# DMM register map
Vendor: Texas Instruments
Peripheral module from a debugger description file (folder omap4430).
Registers are 32-bit, access not given, reset values left out (the file's numbers can be read two ways) unless marked. A register's access mark holds for its fields unless they carry their own. Offsets are as the file gives them; lines under a group give offsets from that group; [hi:lo] are bit positions; {n}, {i} and the like mark numbered series; 'fields as' and 'values as' point back to an identical list; <NAME> marks a mode.

## DMM
0x00 DMM_REVISION ro — DMM Revision Number
  [31:0] REVISION — Revision Number
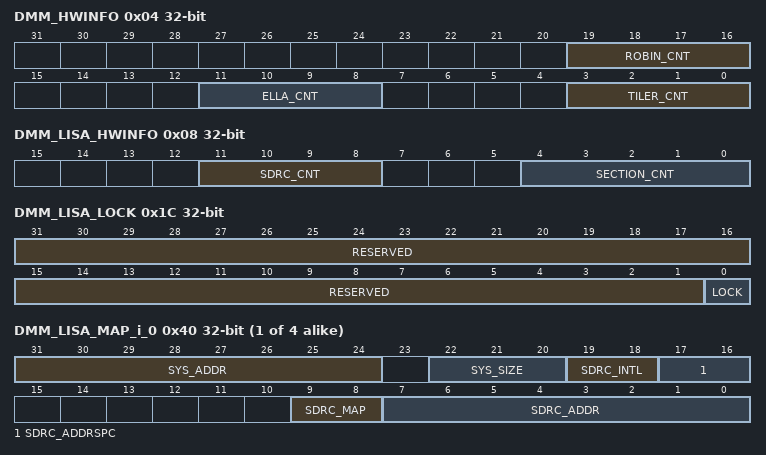
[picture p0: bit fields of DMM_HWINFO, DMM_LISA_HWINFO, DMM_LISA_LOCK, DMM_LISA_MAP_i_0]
0x04 DMM_HWINFO ro — DMM hardware configuration
  [19:16] ROBIN_CNT — Number of ROBIN in the DMM
  [11:8] ELLA_CNT — Number of ELLA in the DMM
  [3:0] TILER_CNT — Number of TILER in the DMM
0x08 DMM_LISA_HWINFO ro — DMM hardware configuration for LISA
  [11:8] SDRC_CNT — Number of attached SDRAM controllers
  [4:0] SECTION_CNT — Number of DMM sections
0x10 DMM_SYSCONFIG — DMM clock management configuration
  [3:2] IDLE_MODE rw — Configuration of the local target state management mode.
    0=Force-idle mode: local target's idle state follows (acknowledges) the system's idle requests unconditionally, that is, regardless of the IP module's internal requirements. Backup mode, for debug only.; 1=No-idle mode: local target never enters idle state. Backup mode, for debug only; 2=Smart-idle mode: local target's idle state eventually follows (acknowledges) the system's idle requests, depending on the IP module's internal requirements. IP module shall not generate (IRQ- or DMA-request-related) wakeup events.
0x1C DMM_LISA_LOCK access per field — DMM memory mapping lock
  [31:1] RESERVED ro — Should be written as 0
  [0] LOCK rw — DMM lock map
    0=LOCK_0_w (No effect (clear on reset only)); 0=LOCK_0_r (un-locked); 1=LOCK_1_r (locked); 1=LOCK_1_w (Locking registers)
{0x40+4i} DMM_LISA_MAP_i_{i} (i=0..3) — DMM memory mapping register
  [31:24] SYS_ADDR rw — DMM system section address MSB for view mapping i
  [22:20] SYS_SIZE rw — DMM system section size for view mapping i
    0=16-MiB section; 1=32-MiB section; 2=64-MiB section; 3=128-MiB section; 4=256-MiB section; 5=512-MiB section; 6=1-GiB section; 7=2-GiB section
  [19:18] SDRC_INTL rw — SDRAM controller interleaving mode 0x0: No interleaving 0x1: 128-byte interleaving 0x2: 256-byte interleaving 0x3: 512-byte interleaving The 128-/256-/512-byte interleaving applies only to nontiled regions. If accesses are made to tiled regions, interleaving is forced to 1kiB. SDRC_INTL is don't care if SDRC_MAP is not 0x3 (no interleaving).
  [17:16] SDRC_ADDRSPC rw — SDRAM controller address space for view mapping i
  [9:8] SDRC_MAP rw — SDRAM controller mapping for view mapping i 0x0: Un-mapped 0x1: Mapped on EMIF1 only (not interleaved) 0x2: Mapped on EMIF2 only (not interleaved) 0x3: Mapped on EMIF1 and EMIF2 (interleaved) To enable interleaving, SDRC_MAP must be 0x3 and SDRC_INTL must be a nonzero value.
  [7:0] SDRC_ADDR rw — SDRAM controller address MSB for view mapping i
0x208 DMM_TILER_HWINFO ro — DMM hardware configuration for TILER
  [4:0] OR_CNT — Number of TILER orientation entries
    1=OR_CNT_1_r (One orientation entry); 2=OR_CNT_2_r (Two orientation entries); 4=OR_CNT_4_r (Four orientation entries); 8=OR_CNT_8_r (Eight orientation entries); 16=OR_CNT_16_r (Sixteen orientation entries)
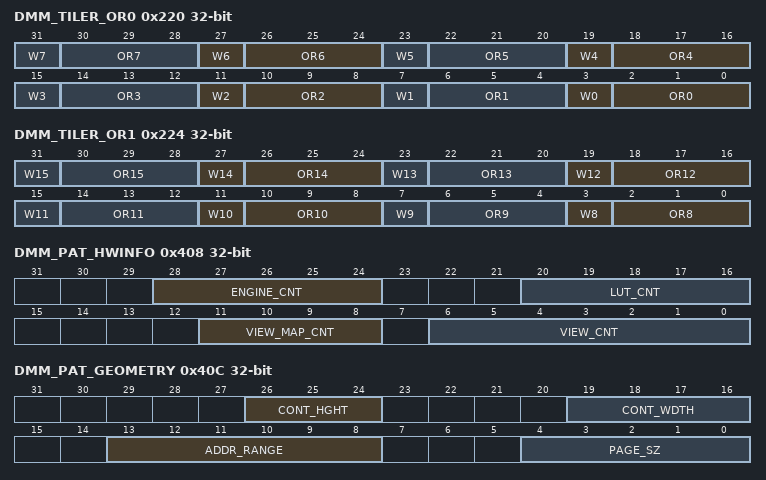
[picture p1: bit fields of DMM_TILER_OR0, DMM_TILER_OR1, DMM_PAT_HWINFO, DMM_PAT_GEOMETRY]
0x220 DMM_TILER_OR0 rw — DMM TILER orientation (initiators 0 to 7)
  [4n+3] W{n} (n=0..7) — Write-enable for OR{n} bit field
    0=W{n}_0_w (OR{n} field is unchanged); 1=W{n}_1_w (OR{n} field is updated)
  [4n+2:4n] OR{n} (n=0..7) — Orientation for initiator {n}
0x224 DMM_TILER_OR1 rw — DMM TILER orientation (initiators 8 to 15)
  [4n-29] W{n} (n=8..15) — Write-enable for OR{n} bit field
    values as DMM_TILER_OR0.W0
  [4n-30:4n-32] OR{n} (n=8..15) — Orientation for initiator {n}
0x408 DMM_PAT_HWINFO ro — DMM hardware configuration for PAT
  [28:24] ENGINE_CNT — Number of PAT refill engines
  [20:16] LUT_CNT — Number of PAT LUT for page-grained physical address translation
  [11:8] VIEW_MAP_CNT — Number of internal PAT view mappings.
    1=VIEW_MAP_CNT_1_r (One view map); 2=VIEW_MAP_CNT_2_r (Two view maps); 4=VIEW_MAP_CNT_4_r (Four view maps); 8=VIEW_MAP_CNT_8_r (Eight view maps)
  [6:0] VIEW_CNT — Number of PAT view entries
    1=VIEW_CNT_1_r (One view entry); 2=VIEW_CNT_2_r (Two view entries); 4=VIEW_CNT_4_r (Four view entries); 8=VIEW_CNT_8_r (Eight view entries); 16=VIEW_CNT_16_r (Sixteen view entries); 32=VIEW_CNT_32_r (Thirty-two view entries); 64=VIEW_CNT_64_r (Sixty-four view entries)
0x40C DMM_PAT_GEOMETRY ro — PAT geometry-related settings
  [26:24] CONT_HGHT — Container height in pages
    1=CONT_HGHT_1_r (Container height of 32 pages); 2=CONT_HGHT_2_r (Container height of 64 pages); 4=CONT_HGHT_4_r (Container height of 128 pages)
  [19:16] CONT_WDTH — Container width in pages
    2=CONT_WDTH_2_r (Container width of 64 pages); 4=CONT_WDTH_4_r (Container width of 128 pages); 8=CONT_WDTH_8_r (Container width of 256 pages)
  [13:8] ADDR_RANGE — PAT output physical address range
    1=ADDR_RANGE_1_r (128-MiB range); 2=ADDR_RANGE_2_r (256-MiB range); 4=ADDR_RANGE_4_r (512-MiB range); 8=ADDR_RANGE_8_r (1-GiB range); 16=ADDR_RANGE_16_r (2-GiB range); 32=ADDR_RANGE_32_r (4-GiB range)
  [4:0] PAGE_SZ — Page size in 4-kiB granularity
    1=PAGE_SZ_1_r (4-kiB page); 4=PAGE_SZ_4_r (16-kiB page); 16=PAGE_SZ_16_r (64-kiB page)
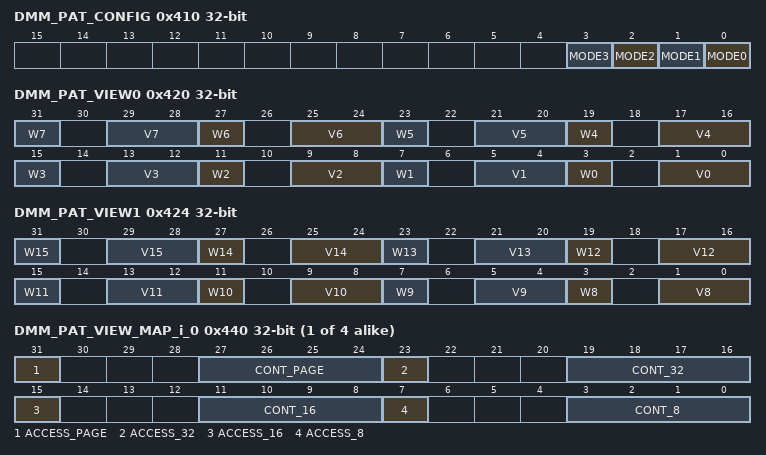
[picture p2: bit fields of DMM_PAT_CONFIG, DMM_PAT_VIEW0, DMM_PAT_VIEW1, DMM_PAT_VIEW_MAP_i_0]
0x410 DMM_PAT_CONFIG access per field — This is the PAT configuration register aimed at defining the major PAT configuration of each refill engine.
  [all] fields
    0=Normal mode; 1=Direct LUT access
  [n] MODE{n} rw (n=0..3) — Mode of refill engine {n}
0x420 DMM_PAT_VIEW0 — DMM PAT View register (initiators 0 to 7)
  [4n+3] W{n} rw (n=0..7) — Write-enable for V{n} bit field
    0=W{n}_0_w (V{n} field is unchanged); 1=W{n}_1_w (V{n} field is updated)
  [4n+1:4n] V{n} rw (n=0..7) — PAT view for initiator {n}
0x424 DMM_PAT_VIEW1 — DMM PAT view register (initiators 8 to 15)
  [4n-29] W{n} rw (n=8..15) — Write-enable for V{n} bit field
    values as DMM_PAT_VIEW0.W0
  [4n-31:4n-32] V{n} rw (n=8..15) — PAT view for initiator {n}
{0x440+4i} DMM_PAT_VIEW_MAP_i_{i} (i=0..3) — PAT view mapping register
  [31] ACCESS_PAGE rw — Kind of access for this page mode container in view mapping i
    0=Direct access, container base address given in CONT_PAGE; 1=Indirect access through the LUT indexed by CONT_PAGE
  [27:24] CONT_PAGE rw — Container for page mode in view mapping i
  [23] ACCESS_32 rw — Kind of access for this 32-bit mode container in view mapping i
    0=Direct access, container base address given in CONT_32; 1=Indirect access through the LUT indexed by CONT_32
  [19:16] CONT_32 rw — Container for 32-bit mode in view mapping i
  [15] ACCESS_16 rw — Kind of access for this 16-bit mode container in view mapping i
    0=Direct access, container base address given in CONT_16; 1=Indirect access through the LUT indexed by CONT_16
  [11:8] CONT_16 rw — Container for 16-bit mode in view mapping i
  [7] ACCESS_8 rw — Kind of access for this 8-bit mode container in view mapping i
    0=Direct access, container base address given in CONT_8; 1=Indirect access through the LUT indexed by CONT_8
  [3:0] CONT_8 rw — Container for 8-bit mode in view mapping i
0x460 DMM_PAT_VIEW_MAP_BASE — Base address of all view mappings
  [31] BASE_ADDR rw — MSB of the PAT view mapping base address
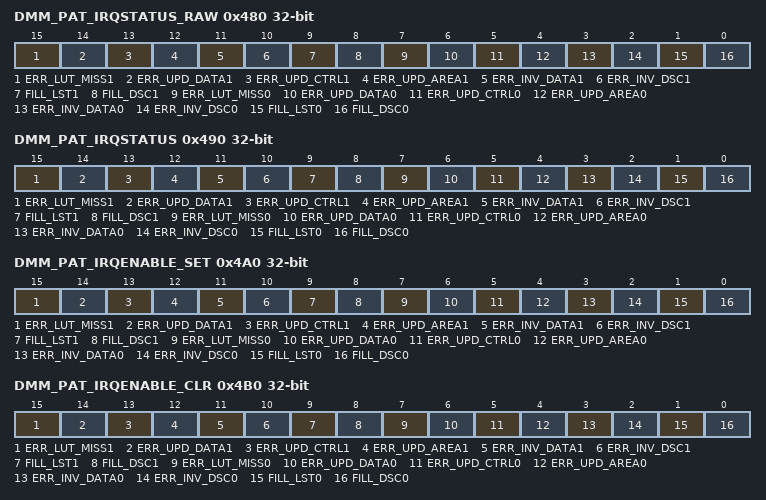
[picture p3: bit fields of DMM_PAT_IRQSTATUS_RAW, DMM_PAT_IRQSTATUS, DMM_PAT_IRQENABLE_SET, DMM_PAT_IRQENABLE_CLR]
0x480 DMM_PAT_IRQSTATUS_RAW — Per-event raw interrupt status vector. Raw status is set even if the related event is not enabled. Write 1 to set the (raw) status, mostly for debug. n = 0 for the first interrupt status raw register, n = 1 for the second interrupt status raw register...
  [15] ERR_LUT_MISS1 — Access to a yet-to-be-refilled area event in area 4.n+1 (access RW W1toSet)
    0=ERR_LUT_MISS1_0_w (Keep current error event); 0=ERR_LUT_MISS1_0_r (No such error event); 1=ERR_LUT_MISS1_1_r (Error event happened); 1=ERR_LUT_MISS1_1_w (Set error event)
  [14] ERR_UPD_DATA1 — Data register update whilst refilling error event in area 4.n+1 (access RW W1toSet)
    0=ERR_UPD_DATA1_0_w (Keep current error event); 0=ERR_UPD_DATA1_0_r (No such error event); 1=ERR_UPD_DATA1_1_r (Error event happened); 1=ERR_UPD_DATA1_1_w (Set error event)
  [13] ERR_UPD_CTRL1 — Control register update whilst refilling error event in area 4.n+1 (access RW W1toSet)
    0=ERR_UPD_CTRL1_0_w (Keep current error event); 0=ERR_UPD_CTRL1_0_r (No such error event); 1=ERR_UPD_CTRL1_1_r (Error event happened); 1=ERR_UPD_CTRL1_1_w (Set error event)
  [12] ERR_UPD_AREA1 — Area register update whilst refilling error event in area 4.n+1 (access RW W1toSet)
    0=ERR_UPD_AREA1_0_w (Keep current error event); 0=ERR_UPD_AREA1_0_r (No such error event); 1=ERR_UPD_AREA1_1_r (Error event happened); 1=ERR_UPD_AREA1_1_w (Set error event)
  [11] ERR_INV_DATA1 — Invalid entry-table pointer error event in area 4.n+1 (access RW W1toSet)
    0=ERR_INV_DATA1_0_w (Keep current error event); 0=ERR_INV_DATA1_0_r (No such error event); 1=ERR_INV_DATA1_1_r (Error event happened); 1=ERR_INV_DATA1_1_w (Set error event)
  [10] ERR_INV_DSC1 — Invalid descriptor pointer error event in area 4.n+1 (access RW W1toSet)
    0=ERR_INV_DSC1_0_w (Keep current error event); 0=ERR_INV_DSC1_0_r (No such error event); 1=ERR_INV_DSC1_1_r (Error event happened); 1=ERR_INV_DSC1_1_w (Set error event)
  [9] FILL_LST1 — End of refill event for the last descriptor in area 4.n+1 (access RW W1toSet)
    0=FILL_LST1_0_w (Keep area 1 refill done event); 0=FILL_LST1_0_r (Area 1 is yet-to-be refilled); 1=FILL_LST1_1_r (Area 1 is refilled); 1=FILL_LST1_1_w (Set area 1 refill done event)
  [8] FILL_DSC1 — End of refill event for any descriptor in area 4.n+1 (access RW W1toSet)
    0=FILL_DSC1_0_w (Keep area 1 refill done event); 0=FILL_DSC1_0_r (Area 1 is yet-to-be refilled); 1=FILL_DSC1_1_r (Area 1 is refilled); 1=FILL_DSC1_1_w (Set area 1 refill done event)
  [7] ERR_LUT_MISS0 — Access to a yet-to-be-refilled area event in area 4.n (access RW W1toSet)
    0=ERR_LUT_MISS0_0_w (Keep current error event); 0=ERR_LUT_MISS0_0_r (No such error event); 1=ERR_LUT_MISS0_1_r (Error event happened); 1=ERR_LUT_MISS0_1_w (Set error event)
  [6] ERR_UPD_DATA0 — Data register update whilst refilling error event in area 4.n (access RW W1toSet)
    0=ERR_UPD_DATA0_0_w (Keep current error event); 0=ERR_UPD_DATA0_0_r (No such error event); 1=ERR_UPD_DATA0_1_r (Error event happened); 1=ERR_UPD_DATA0_1_w (Set error event)
  [5] ERR_UPD_CTRL0 — Control register update whilst refilling error event in area 4.n (access RW W1toSet)
    0=ERR_UPD_CTRL0_0_w (Keep current error event); 0=ERR_UPD_CTRL0_0_r (No such error event); 1=ERR_UPD_CTRL0_1_r (Error event happened); 1=ERR_UPD_CTRL0_1_w (Set error event)
  [4] ERR_UPD_AREA0 — Area register update whilst refilling error event in area 4.n (access RW W1toSet)
    0=ERR_UPD_AREA0_0_w (Keep current error event); 0=ERR_UPD_AREA0_0_r (No such error event); 1=ERR_UPD_AREA0_1_r (Error event happened); 1=ERR_UPD_AREA0_1_w (Set error event)
  [3] ERR_INV_DATA0 — Invalid entry-table pointer error event in area 4.n (access RW W1toSet)
    0=ERR_INV_DATA0_0_w (Keep current error event); 0=ERR_INV_DATA0_0_r (No such error event); 1=ERR_INV_DATA0_1_r (Error event happened); 1=ERR_INV_DATA0_1_w (Set error event)
  [2] ERR_INV_DSC0 — Invalid descriptor pointer error event in area 4.n (access RW W1toSet)
    0=ERR_INV_DSC0_0_w (Keep current error event); 0=ERR_INV_DSC0_0_r (No such error event); 1=ERR_INV_DSC0_1_r (Error event happened); 1=ERR_INV_DSC0_1_w (Set error event)
  [1] FILL_LST0 — End of refill event for the last descriptor in area 4.n (access RW W1toSet)
    0=FILL_LST0_0_w (Keep area 0 refill done event); 0=FILL_LST0_0_r (Area 0 is yet-to-be refilled); 1=FILL_LST0_1_r (Area 0 is refilled); 1=FILL_LST0_1_w (Set area 0 refill done event)
  [0] FILL_DSC0 — End of refill event for any descriptor in area 4.n (access RW W1toSet)
    0=FILL_DSC0_0_w (Keep area 0 refill done event); 0=FILL_DSC0_0_r (Area 0 is yet-to-be refilled); 1=FILL_DSC0_1_r (Area 0 is refilled); 1=FILL_DSC0_1_w (Set area 0 refill done event)
0x490 DMM_PAT_IRQSTATUS — Per-event 'enabled' interrupt status vector. Enabled status is not set unless the event is enabled. Write 1 to clear the status after interrupt has been serviced (raw status gets cleared, that is, even if not enabled). n = 0 for the first interrupt status register, n = 1 for the second interrupt status register...
  [15] ERR_LUT_MISS1 — Access to a yet-to-be-refilled area event in area 4.n+1 (access RW W1toClr)
    0=ERR_LUT_MISS1_0_w (Keep current maskable error event); 0=ERR_LUT_MISS1_0_r (No such error event or this event is masked); 1=ERR_LUT_MISS1_1_r (Error event happened); 1=ERR_LUT_MISS1_1_w (Clear this maskable error event)
  [14] ERR_UPD_DATA1 — Data register update whilst refilling error event in area 4.n+1 (access RW W1toClr)
    0=ERR_UPD_DATA1_0_w (Keep current maskable error event); 0=ERR_UPD_DATA1_0_r (No such error event or this event is masked); 1=ERR_UPD_DATA1_1_r (Error event happened); 1=ERR_UPD_DATA1_1_w (Clear this maskable error event)
  [13] ERR_UPD_CTRL1 — Control register update whilst refilling error event in area 4.n+1 (access RW W1toClr)
    0=ERR_UPD_CTRL1_0_w (Keep current maskable error event); 0=ERR_UPD_CTRL1_0_r (No such error event or this event is masked); 1=ERR_UPD_CTRL1_1_r (Error event happened); 1=ERR_UPD_CTRL1_1_w (Clear this maskable error event)
  [12] ERR_UPD_AREA1 — Area register update whilst refilling error event in area 4.n+1 (access RW W1toClr)
    0=ERR_UPD_AREA1_0_w (Keep current maskable error event); 0=ERR_UPD_AREA1_0_r (No such error event or this event is masked); 1=ERR_UPD_AREA1_1_r (Error event happened); 1=ERR_UPD_AREA1_1_w (Clear this maskable error event)
  [11] ERR_INV_DATA1 — Invalid entry-table pointer error event in area 4.n+1 (access RW W1toClr)
    0=ERR_INV_DATA1_0_w (Keep current maskable error event); 0=ERR_INV_DATA1_0_r (No such error event or this event is masked); 1=ERR_INV_DATA1_1_r (Error event happened); 1=ERR_INV_DATA1_1_w (Clear this maskable error event)
  [10] ERR_INV_DSC1 — Invalid descriptor pointer error event in area 4.n+1 (access RW W1toClr)
    0=ERR_INV_DSC1_0_w (Keep current maskable error event); 0=ERR_INV_DSC1_0_r (No such error event or this event is masked); 1=ERR_INV_DSC1_1_r (Error event happened); 1=ERR_INV_DSC1_1_w (Clear this maskable error event)
  [9] FILL_LST1 — End of refill event for the last descriptor in area 4.n+1 (access RW W1toClr)
    0=FILL_LST1_0_w (Keep current area refill done maskable event); 0=FILL_LST1_0_r (Current area is yet-to-be refilled or this event is masked); 1=FILL_LST1_1_r (Current area is refilled); 1=FILL_LST1_1_w (Clear current area refill done maskable event)
  [8] FILL_DSC1 — End of refill event for any descriptor in area 4.n+1 (access RW W1toClr)
    0=FILL_DSC1_0_w (Keep current area refill done maskable event); 0=FILL_DSC1_0_r (Current area is yet-to-be refilled or this event is masked); 1=FILL_DSC1_1_r (Current area is refilled); 1=FILL_DSC1_1_w (Clear current area refill done maskable event)
  [7] ERR_LUT_MISS0 — Access to a yet-to-be-refilled area event in area 4.n (access RW W1toClr)
    0=ERR_LUT_MISS0_0_w (Keep current maskable error event); 0=ERR_LUT_MISS0_0_r (No such error event or this event is masked); 1=ERR_LUT_MISS0_1_r (Error event happened); 1=ERR_LUT_MISS0_1_w (Clear this maskable error event)
  [6] ERR_UPD_DATA0 — Data register update whilst refilling error event in area 4.n (access RW W1toClr)
    0=ERR_UPD_DATA0_0_w (Keep current maskable error event); 0=ERR_UPD_DATA0_0_r (No such error event or this event is masked); 1=ERR_UPD_DATA0_1_r (Error event happened); 1=ERR_UPD_DATA0_1_w (Clear this maskable error event)
  [5] ERR_UPD_CTRL0 — Control register update whilst refilling error event in area 4.n (access RW W1toClr)
    0=ERR_UPD_CTRL0_0_w (Keep current maskable error event); 0=ERR_UPD_CTRL0_0_r (No such error event or this event is masked); 1=ERR_UPD_CTRL0_1_r (Error event happened); 1=ERR_UPD_CTRL0_1_w (Clear this maskable error event)
  [4] ERR_UPD_AREA0 — Area register update whilst refilling error event in area 4.n (access RW W1toClr)
    0=ERR_UPD_AREA0_0_w (Keep current maskable error event); 0=ERR_UPD_AREA0_0_r (No such error event or this event is masked); 1=ERR_UPD_AREA0_1_r (Error event happened); 1=ERR_UPD_AREA0_1_w (Clear this maskable error event)
  [3] ERR_INV_DATA0 — Invalid entry-table pointer error event in area 4.n (access RW W1toClr)
    0=ERR_INV_DATA0_0_w (Keep current maskable error event); 0=ERR_INV_DATA0_0_r (No such error event or this event is masked); 1=ERR_INV_DATA0_1_r (Error event happened); 1=ERR_INV_DATA0_1_w (Clear this maskable error event)
  [2] ERR_INV_DSC0 — Invalid descriptor pointer error event in area 4.n (access RW W1toClr)
    0=ERR_INV_DSC0_0_w (Keep current maskable error event); 0=ERR_INV_DSC0_0_r (No such error event or this event is masked); 1=ERR_INV_DSC0_1_r (Error event happened); 1=ERR_INV_DSC0_1_w (Clear this maskable error event)
  [1] FILL_LST0 — End of refill event for the last descriptor in area 4.n (access RW W1toClr)
    0=FILL_LST0_0_w (Keep current area refill done maskable event); 0=FILL_LST0_0_r (Current area is yet-to-be refilled or this event is masked); 1=FILL_LST0_1_r (Current area is refilled); 1=FILL_LST0_1_w (Clear current area refill done maskable event)
  [0] FILL_DSC0 — End of refill event for any descriptor in area 4.n (access RW W1toClr)
    0=FILL_DSC0_0_w (Keep current area refill done maskable event); 0=FILL_DSC0_0_r (Current area is yet-to-be refilled or this event is masked); 1=FILL_DSC0_1_r (Current area is refilled); 1=FILL_DSC0_1_w (Clear current area refill done maskable event)
0x4A0 DMM_PAT_IRQENABLE_SET — Per-event interrupt enable bit vector. Write 1 to set (enable interrupt). Readout equal to corresponding _CLR register. n = 0 for the first interrupt enable set register, n = 1 for the second interrupt enable set register...
  [15] ERR_LUT_MISS1 — Unexpected access to a yet-to-be-refilled area interrupt source mask for area 4.n+1 (access RW W1toSet)
    0=ERR_LUT_MISS1_0_w (Keep current mask of this interrupt source); 0=ERR_LUT_MISS1_0_r (This interrupt source is disabled (masked)); 1=ERR_LUT_MISS1_1_r (This interrupt source is enabled (unmasked)); 1=ERR_LUT_MISS1_1_w (Enable (unmask) this interrupt source)
  [14] ERR_UPD_DATA1 — Unexpected data register update whilst refilling interrupt source mask for area 4.n+1 (access RW W1toSet)
    0=ERR_UPD_DATA1_0_w (Keep current mask of this interrupt source); 0=ERR_UPD_DATA1_0_r (This interrupt source is disabled (masked)); 1=ERR_UPD_DATA1_1_r (This interrupt source is enabled (unmasked)); 1=ERR_UPD_DATA1_1_w (Enable (unmask) this interrupt source)
  [13] ERR_UPD_CTRL1 — Unexpected control register update whilst refilling interrupt source mask for area 4.n+1 (access RW W1toSet)
    0=ERR_UPD_CTRL1_0_w (Keep current mask of this interrupt source); 0=ERR_UPD_CTRL1_0_r (This interrupt source is disabled (masked)); 1=ERR_UPD_CTRL1_1_r (This interrupt source is enabled (unmasked)); 1=ERR_UPD_CTRL1_1_w (Enable (unmask) this interrupt source)
  [12] ERR_UPD_AREA1 — Unexpected area register update whilst refilling interrupt source mask for area 4.n+1 (access RW W1toSet)
    0=ERR_UPD_AREA1_0_w (Keep current mask of this interrupt source); 0=ERR_UPD_AREA1_0_r (This interrupt source is disabled (masked)); 1=ERR_UPD_AREA1_1_r (This interrupt source is enabled (unmasked)); 1=ERR_UPD_AREA1_1_w (Enable (unmask) this interrupt source)
  [11] ERR_INV_DATA1 — Invalid entry-table pointer interrupt source mask for area 4.n+1 (access RW W1toSet)
    0=ERR_INV_DATA1_0_w (Keep current mask of this interrupt source); 0=ERR_INV_DATA1_0_r (This interrupt source is disabled (masked)); 1=ERR_INV_DATA1_1_r (This interrupt source is enabled (unmasked)); 1=ERR_INV_DATA1_1_w (Enable (unmask) this interrupt source)
  [10] ERR_INV_DSC1 — Invalid descriptor pointer interrupt source mask for area 4.n+1 (access RW W1toSet)
    0=ERR_INV_DSC1_0_w (Keep current mask of this interrupt source); 0=ERR_INV_DSC1_0_r (This interrupt source is disabled (masked)); 1=ERR_INV_DSC1_1_r (This interrupt source is enabled (unmasked)); 1=ERR_INV_DSC1_1_w (Enable (unmask) this interrupt source)
  [9] FILL_LST1 — End of refill interrupt source mask for the last descriptior in area 4.n+1 (access RW W1toSet)
    0=FILL_LST1_0_w (Keep current mask of this interrupt source); 0=FILL_LST1_0_r (This interrupt source is disabled (masked)); 1=FILL_LST1_1_r (This interrupt source is enabled (unmasked)); 1=FILL_LST1_1_w (Enable (unmask) this interrupt source)
  [8] FILL_DSC1 — End of refill interrupt source mask for any descriptior in area 4.n+1 (access RW W1toSet)
    0=FILL_DSC1_0_w (Keep current mask of this interrupt source); 0=FILL_DSC1_0_r (This interrupt source is disabled (masked)); 1=FILL_DSC1_1_r (This interrupt source is enabled (unmasked)); 1=FILL_DSC1_1_w (Enable (unmask) this interrupt source)
  [7] ERR_LUT_MISS0 — Unexpected access to a yet-to-be-refilled area interrupt source mask for area 4.n (access RW W1toSet)
    0=ERR_LUT_MISS0_0_w (Keep current mask of this interrupt source); 0=ERR_LUT_MISS0_0_r (This interrupt source is disabled (masked)); 1=ERR_LUT_MISS0_1_r (This interrupt source is enabled (unmasked)); 1=ERR_LUT_MISS0_1_w (Enable (unmask) this interrupt source)
  [6] ERR_UPD_DATA0 — Unexpected data register update whilst refilling interrupt source mask for area 4.n (access RW W1toSet)
    0=ERR_UPD_DATA0_0_w (Keep current mask of this interrupt source); 0=ERR_UPD_DATA0_0_r (This interrupt source is disabled (masked)); 1=ERR_UPD_DATA0_1_r (This interrupt source is enabled (unmasked)); 1=ERR_UPD_DATA0_1_w (Enable (unmask) this interrupt source)
  [5] ERR_UPD_CTRL0 — Unexpected control register update whilst refilling interrupt source mask for area 4.n (access RW W1toSet)
    0=ERR_UPD_CTRL0_0_w (Keep current mask of this interrupt source); 0=ERR_UPD_CTRL0_0_r (This interrupt source is disabled (masked)); 1=ERR_UPD_CTRL0_1_r (This interrupt source is enabled (unmasked)); 1=ERR_UPD_CTRL0_1_w (Enable (unmask) this interrupt source)
  [4] ERR_UPD_AREA0 — Unexpected area register update whilst refilling interrupt source mask for area 4.n (access RW W1toSet)
    0=ERR_UPD_AREA0_0_w (Keep current mask of this interrupt source); 0=ERR_UPD_AREA0_0_r (This interrupt source is disabled (masked)); 1=ERR_UPD_AREA0_1_r (This interrupt source is enabled (unmasked)); 1=ERR_UPD_AREA0_1_w (Enable (unmask) this interrupt source)
  [3] ERR_INV_DATA0 — Invalid entry-table pointer interrupt source mask for area 4.n (access RW W1toSet)
    0=ERR_INV_DATA0_0_w (Keep current mask of this interrupt source); 0=ERR_INV_DATA0_0_r (This interrupt source is disabled (masked)); 1=ERR_INV_DATA0_1_r (This interrupt source is enabled (unmasked)); 1=ERR_INV_DATA0_1_w (Enable (unmask) this interrupt source)
  [2] ERR_INV_DSC0 — Invalid descriptor pointer interrupt source mask for area 4.n (access RW W1toSet)
    0=ERR_INV_DSC0_0_w (Keep current mask of this interrupt source); 0=ERR_INV_DSC0_0_r (This interrupt source is disabled (masked)); 1=ERR_INV_DSC0_1_r (This interrupt source is enabled (unmasked)); 1=ERR_INV_DSC0_1_w (Enable (unmask) this interrupt source)
  [1] FILL_LST0 — End of refill interrupt source mask for the last descriptior in area 4.n (access RW W1toSet)
    0=FILL_LST0_0_w (Keep current mask of this interrupt source); 0=FILL_LST0_0_r (This interrupt source is disabled (masked)); 1=FILL_LST0_1_r (This interrupt source is enabled (unmasked)); 1=FILL_LST0_1_w (Enable (unmask) this interrupt source)
  [0] FILL_DSC0 — End of refill interrupt source mask for any descriptior in area 4.n (access RW W1toSet)
    0=FILL_DSC0_0_w (Keep current mask of this interrupt source); 0=FILL_DSC0_0_r (This interrupt source is disabled (masked)); 1=FILL_DSC0_1_r (This interrupt source is enabled (unmasked)); 1=FILL_DSC0_1_w (Enable (unmask) this interrupt source)
0x4B0 DMM_PAT_IRQENABLE_CLR — Per-event interrupt enable bit vector. Write 1 to clear (disable interrupt). Readout equal to corresponding _SET register. n = 0 for the first interrupt enable clear register, n = 1 for the second interrupt enable clear register...
  [15] ERR_LUT_MISS1 — Unexpected access to a yet-to-be-refilled area interrupt source mask for area 4.n+1 (access RW W1toClr)
    0=ERR_LUT_MISS1_0_w (Keep current mask of this interrupt source); 0=ERR_LUT_MISS1_0_r (This interrupt source is disabled (masked)); 1=ERR_LUT_MISS1_1_r (This interrupt source is enabled (unmasked)); 1=ERR_LUT_MISS1_1_w (Disable (mask) this interrupt source)
  [14] ERR_UPD_DATA1 — Unexpected data register update whilst refilling interrupt source mask for area 4.n+1 (access RW W1toClr)
    0=ERR_UPD_DATA1_0_w (Keep current mask of this interrupt source); 0=ERR_UPD_DATA1_0_r (This interrupt source is disabled (masked)); 1=ERR_UPD_DATA1_1_r (This interrupt source is enabled (unmasked)); 1=ERR_UPD_DATA1_1_w (Disable (mask) this interrupt source)
  [13] ERR_UPD_CTRL1 — Unexpected control register update whilst refilling interrupt source mask for area 4.n+1 (access RW W1toClr)
    0=ERR_UPD_CTRL1_0_w (Keep current mask of this interrupt source); 0=ERR_UPD_CTRL1_0_r (This interrupt source is disabled (masked)); 1=ERR_UPD_CTRL1_1_r (This interrupt source is enabled (unmasked)); 1=ERR_UPD_CTRL1_1_w (Disable (mask) this interrupt source)
  [12] ERR_UPD_AREA1 — Unexpected area register update whilst refilling interrupt source mask for area 4.n+1 (access RW W1toClr)
    0=ERR_UPD_AREA1_0_w (Keep current mask of this interrupt source); 0=ERR_UPD_AREA1_0_r (This interrupt source is disabled (masked)); 1=ERR_UPD_AREA1_1_r (This interrupt source is enabled (unmasked)); 1=ERR_UPD_AREA1_1_w (Disable (mask) this interrupt source)
  [11] ERR_INV_DATA1 — Invalid entry-table pointer interrupt source mask for area 4.n+1 (access RW W1toClr)
    0=ERR_INV_DATA1_0_w (Keep current mask of this interrupt source); 0=ERR_INV_DATA1_0_r (This interrupt source is disabled (masked)); 1=ERR_INV_DATA1_1_r (This interrupt source is enabled (unmasked)); 1=ERR_INV_DATA1_1_w (Disable (mask) this interrupt source)
  [10] ERR_INV_DSC1 — Invalid descriptor pointer interrupt source mask for area 4.n+1 (access RW W1toClr)
    0=ERR_INV_DSC1_0_w (Keep current mask of this interrupt source); 0=ERR_INV_DSC1_0_r (This interrupt source is disabled (masked)); 1=ERR_INV_DSC1_1_r (This interrupt source is enabled (unmasked)); 1=ERR_INV_DSC1_1_w (Disable (mask) this interrupt source)
  [9] FILL_LST1 — End of refill interrupt source mask for the last descriptior in area 4.n+1 (access RW W1toClr)
    0=FILL_LST1_0_w (Keep current mask of this interrupt source); 0=FILL_LST1_0_r (This interrupt source is disabled (masked)); 1=FILL_LST1_1_r (This interrupt source is enabled (unmasked)); 1=FILL_LST1_1_w (Disable (mask) this interrupt source)
  [8] FILL_DSC1 — End of refill interrupt source mask for any descriptior in area 4.n+1 (access RW W1toClr)
    0=FILL_DSC1_0_w (Keep current mask of this interrupt source); 0=FILL_DSC1_0_r (This interrupt source is disabled (masked)); 1=FILL_DSC1_1_r (This interrupt source is enabled (unmasked)); 1=FILL_DSC1_1_w (Disable (mask) this interrupt source)
  [7] ERR_LUT_MISS0 — Unexpected access to a yet-to-be-refilled area interrupt source mask for area 4.n (access RW W1toClr)
    0=ERR_LUT_MISS0_0_w (Keep current mask of this interrupt source); 0=ERR_LUT_MISS0_0_r (This interrupt source is disabled (masked)); 1=ERR_LUT_MISS0_1_r (This interrupt source is enabled (unmasked)); 1=ERR_LUT_MISS0_1_w (Disable (mask) this interrupt source)
  [6] ERR_UPD_DATA0 — Unexpected data register update whilst refilling interrupt source mask for area 4.n (access RW W1toClr)
    0=ERR_UPD_DATA0_0_w (Keep current mask of this interrupt source); 0=ERR_UPD_DATA0_0_r (This interrupt source is disabled (masked)); 1=ERR_UPD_DATA0_1_r (This interrupt source is enabled (unmasked)); 1=ERR_UPD_DATA0_1_w (Disable (mask) this interrupt source)
  [5] ERR_UPD_CTRL0 — Unexpected control register update whilst refilling interrupt source mask for area 4.n (access RW W1toClr)
    0=ERR_UPD_CTRL0_0_w (Keep current mask of this interrupt source); 0=ERR_UPD_CTRL0_0_r (This interrupt source is disabled (masked)); 1=ERR_UPD_CTRL0_1_r (This interrupt source is enabled (unmasked)); 1=ERR_UPD_CTRL0_1_w (Disable (mask) this interrupt source)
  [4] ERR_UPD_AREA0 — Unexpected area register update whilst refilling interrupt source mask for area 4.n (access RW W1toClr)
    0=ERR_UPD_AREA0_0_w (Keep current mask of this interrupt source); 0=ERR_UPD_AREA0_0_r (This interrupt source is disabled (masked)); 1=ERR_UPD_AREA0_1_r (This interrupt source is enabled (unmasked)); 1=ERR_UPD_AREA0_1_w (Disable (mask) this interrupt source)
  [3] ERR_INV_DATA0 — Invalid entry-table pointer interrupt source mask for area 4.n (access RW W1toClr)
    0=ERR_INV_DATA0_0_w (Keep current mask of this interrupt source); 0=ERR_INV_DATA0_0_r (This interrupt source is disabled (masked)); 1=ERR_INV_DATA0_1_r (This interrupt source is enabled (unmasked)); 1=ERR_INV_DATA0_1_w (Disable (mask) this interrupt source)
  [2] ERR_INV_DSC0 — Invalid descriptor pointer interrupt source mask for area 4.n (access RW W1toClr)
    0=ERR_INV_DSC0_0_w (Keep current mask of this interrupt source); 0=ERR_INV_DSC0_0_r (This interrupt source is disabled (masked)); 1=ERR_INV_DSC0_1_r (This interrupt source is enabled (unmasked)); 1=ERR_INV_DSC0_1_w (Disable (mask) this interrupt source)
  [1] FILL_LST0 — End of refill interrupt source mask for the last descriptior in area 4.n (access RW W1toClr)
    0=FILL_LST0_0_w (Keep current mask of this interrupt source); 0=FILL_LST0_0_r (This interrupt source is disabled (masked)); 1=FILL_LST0_1_r (This interrupt source is enabled (unmasked)); 1=FILL_LST0_1_w (Disable (mask) this interrupt source)
  [0] FILL_DSC0 — End of refill interrupt source mask for any descriptior in area 4.n (access RW W1toClr)
    0=FILL_DSC0_0_w (Keep current mask of this interrupt source); 0=FILL_DSC0_0_r (This interrupt source is disabled (masked)); 1=FILL_DSC0_1_r (This interrupt source is enabled (unmasked)); 1=FILL_DSC0_1_w (Disable (mask) this interrupt source)
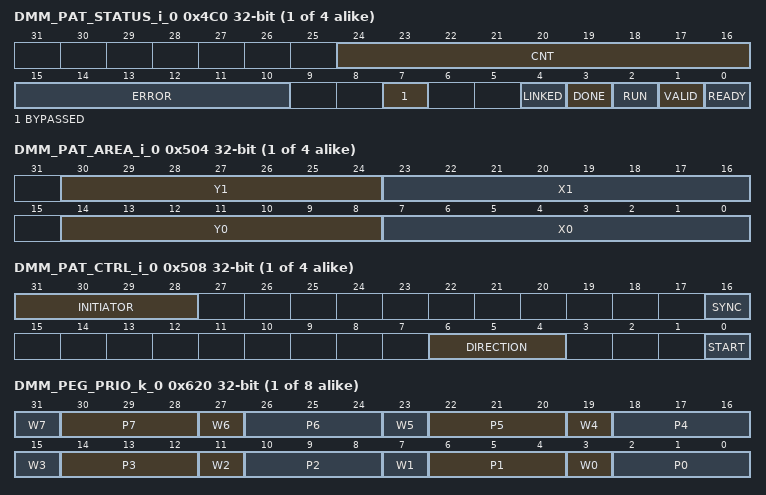
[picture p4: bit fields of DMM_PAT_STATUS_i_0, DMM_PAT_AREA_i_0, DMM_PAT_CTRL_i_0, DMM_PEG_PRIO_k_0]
{0x4C0+4i} DMM_PAT_STATUS_i_{i} ro (i=0..3) — Status register for each refill engine n = 0 for the first engine status register, n = 1 for the second engine status register...
  [24:16] CNT — Counter of remaining lines to reload for engine n
  [15:10] ERROR — Error happened in engine n
    0=ERROR_0_r (No error); 1=ERROR_1_r (Invalid descriptor provided); 2=ERROR_2_r (Invalid data pointer provided); 4=ERROR_4_r (Unexpected area register update whilst refilling); 8=ERROR_8_r (Unexpected control register update whilst refilling); 16=ERROR_16_r (Unexpected data register update whilst refilling); 32=ERROR_32_r (Unexpected access to a yet-to-be-refilled location)
  [7] BYPASSED — Engine n is bypassed. Direct access to the LUT is provided.
  [4] LINKED — Area reconfiguration link asserted for engine n
  [3] DONE — Area reloading finished for engine n
  [2] RUN — Area currently reloading for engine n
  [1] VALID — Valid area description for engine n
  [0] READY — Area registers ready for engine n
{0x500+0x10*i} DMM_PAT_DESCR_i_{i} (i=0..3) — Physical address of the next table refill descriptor n = 0 for the descriptor register of the first engine, n = 1 for the descriptor register of the second engine... Writing to this register aborts the current ongoing area reload and resets the corresponding DMM_PAT_AREA__x, DMM_PAT_CTRL__x and DMM_PAT_DATA__x registers
  [31:4] ADDR — Physical address of the next table refill descriptor of engine n (access RW WtoClr)
{0x504+0x10*i} DMM_PAT_AREA_i_{i} (i=0..3) — Area definition for DMM physical address translator n = 0 for the area register of the first engine, n = 1 for the area register of the second engine...
  [30:24] Y1 rw — Y-coordinate of the bottom right corner of the PAT area for engine n
  [23:16] X1 rw — X-coordinate of the bottom right corner of the PAT area for engine n
  [14:8] Y0 rw — Y-coordinate of the top left corner of the PAT area for engine n
  [7:0] X0 rw — X-coordinate of the top left corner of the PAT area for engine n
{0x508+0x10*i} DMM_PAT_CTRL_i_{i} (i=0..3) — DMM physical address translator control register n = 0 for the control register of the first engine, n = 1 for the control register of the second engine...
  [31:28] INITIATOR rw — DMM PAT initiator for synchronisation in engine n
  [16] SYNC rw — DMM PAT table reload synchronisation for engine n
    0=Not synchronized; 1=Synchronised
  [6:4] DIRECTION rw — Direction of this PAT table refill for engine n
  [0] START rw — Starting a PAT table refill with engine n
{0x50C+0x10*i} DMM_PAT_DATA_i_{i} (i=0..3) — Physical address of the current table refill entry data n = 0 for the data register of the first engine, n = 1 for the data register of the second engine...
  [31:4] ADDR rw — Physical address of the current table refill entry data or single actual entry data when in manual mode for engine n
0x608 DMM_PEG_HWINFO ro — DMM hardware configuration for PEG
  [6:0] PRIO_CNT — Number of PEG priority entries
    1=PRIO_CNT_1_r (One priority entry); 2=PRIO_CNT_2_r (Two priority entries); 4=PRIO_CNT_4_r (Four priority entries); 8=PRIO_CNT_8_r (Eight priority entries); 16=PRIO_CNT_16_r (Sixteen priority entries); 32=PRIO_CNT_32_r (Thirty-two priority entries); 64=PRIO_CNT_64_r (Sixty-four priority entries)
{0x620+4i} DMM_PEG_PRIO_k_{i} rw (i=0..7) — DMM PEG Priority register
  [4n+3] W{n} (n=0..7) — Write-enable for P{n} bit field
    0=W{n}_0_w (P{n} field is unchanged); 1=W{n}_1_w (P{n} field is updated)
  [4n+2:4n] P{n} (n=1..7) — Priority for initiator 8.k+{n}
  [2:0] P0 — Priority for initiator 8.k
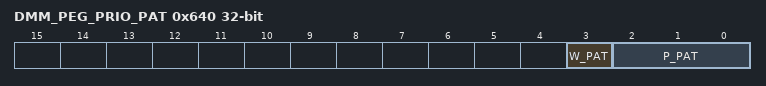
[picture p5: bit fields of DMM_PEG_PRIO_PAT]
0x640 DMM_PEG_PRIO_PAT — DMM PEG Priority register for the internal PAT engine.
  [3] W_PAT rw — Write-enable for P_PAT bit field
    0=W_PAT_0_w (P_PAT field is updated); 1=W_PAT_1_w (P_PAT field is unchanged)
  [2:0] P_PAT rw — Priority for PAT engine
